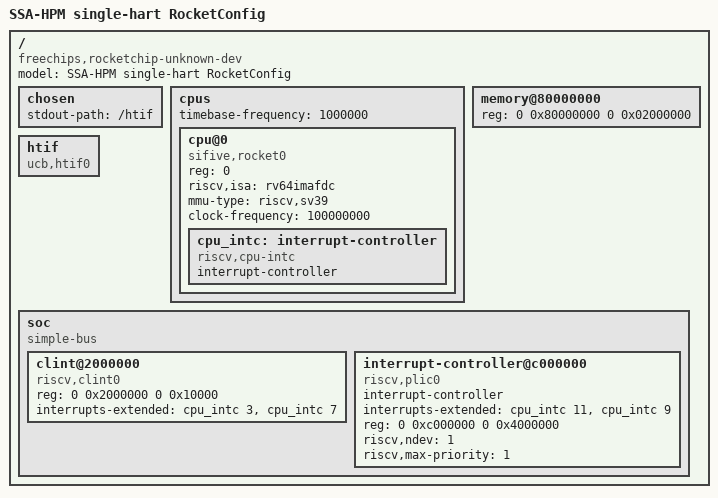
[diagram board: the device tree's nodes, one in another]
/dts-v1/;
/* Minimal software view of the existing single-hart RocketConfig.
 * Addresses, interrupt contexts and timebase match generated RocketConfig DTS.
 * Only 32 MiB is assigned to Linux; other DRAM remains outside its allocator.
 * UART/SPI and other unused peripherals are intentionally not instantiated here.
 */
/ {
 #address-cells = <2>;
 #size-cells = <2>;
 compatible = "freechips,rocketchip-unknown-dev";
 model = "SSA-HPM single-hart RocketConfig";
 chosen { stdout-path = "/htif"; };
 cpus {
  #address-cells = <1>; #size-cells = <0>; timebase-frequency = <1000000>;
  cpu@0 {
   device_type = "cpu"; reg = <0>; status = "okay";
   compatible = "sifive,rocket0", "riscv";
   riscv,isa = "rv64imafdc"; mmu-type = "riscv,sv39";
   clock-frequency = <100000000>;
   cpu_intc: interrupt-controller { #interrupt-cells = <1>; compatible = "riscv,cpu-intc"; interrupt-controller; };
  };
 };
 memory@80000000 { device_type = "memory"; reg = <0 0x80000000 0 0x02000000>; };
 htif { compatible = "ucb,htif0"; };
 soc {
  #address-cells = <2>; #size-cells = <2>; compatible = "simple-bus"; ranges;
  clint@2000000 { compatible = "riscv,clint0"; reg = <0 0x2000000 0 0x10000>; interrupts-extended = <&cpu_intc 3 &cpu_intc 7>; };
  interrupt-controller@c000000 {
   #interrupt-cells = <1>; compatible = "riscv,plic0"; interrupt-controller;
   interrupts-extended = <&cpu_intc 11 &cpu_intc 9>;
   reg = <0 0xc000000 0 0x4000000>; riscv,ndev = <1>; riscv,max-priority = <1>;
  };
 };
};
